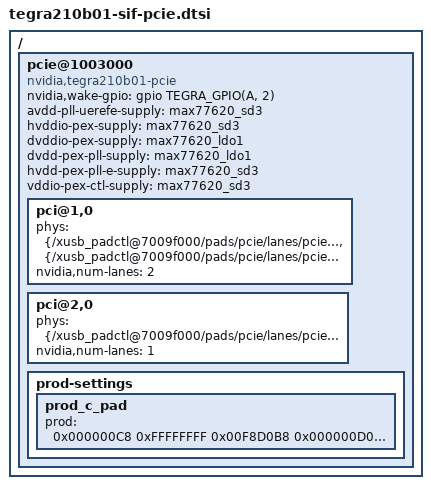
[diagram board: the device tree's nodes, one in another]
/*
 * tegra210b01-sif-pci.dtsi
 *
 * Copyright (c) 2018, NVIDIA CORPORATION.  All rights reserved.
 *
 * This program is free software; you can redistribute it and/or modify
 * it under the terms of the GNU General Public License as published by
 * the Free Software Foundation; version 2 of the License.
 *
 * This program is distributed in the hope that it will be useful, but WITHOUT
 * ANY WARRANTY; without even the implied warranty of MERCHANTABILITY or
 * FITNESS FOR A PARTICULAR PURPOSE.  See the GNU General Public License for
 * more details.
 *
 * You should have received a copy of the GNU General Public License along
 * with this program; if not, write to the Free Software Foundation, Inc.,
 * 51 Franklin Street, Fifth Floor, Boston, MA  02110-1301, USA.
 *
 */
/ {
	pcie@1003000 {
		compatible = "nvidia,tegra210b01-pcie";
		/delete-property/ iommus;
		/delete-property/ iommu-map;
		/delete-property/ iommu-map-mask;
		nvidia,wake-gpio = <&gpio TEGRA_GPIO(A, 2) 0>;
		avdd-pll-uerefe-supply = <&max77620_sd3>;
		hvddio-pex-supply = <&max77620_sd3>;
		dvddio-pex-supply = <&max77620_ldo1>;
		dvdd-pex-pll-supply = <&max77620_ldo1>;
		hvdd-pex-pll-e-supply = <&max77620_sd3>;
		vddio-pex-ctl-supply = <&max77620_sd3>;
		status = "okay";

		pci@1,0 {
			phys = <&{/xusb_padctl@7009f000/pads/pcie/lanes/pcie-3}>,
				<&{/xusb_padctl@7009f000/pads/pcie/lanes/pcie-2}>;
			phy-names = "pcie-0", "pcie-1";
			nvidia,num-lanes = <2>;
			status = "okay";
		};

		pci@2,0 {
			phys = <&{/xusb_padctl@7009f000/pads/pcie/lanes/pcie-0}>;
			phy-names = "pcie-0";
			nvidia,num-lanes = <1>;
			status = "okay";
		};

		prod-settings {
			prod_c_pad {
				prod = <
					0x000000C8 0xFFFFFFFF 0x00F8D0B8        // PADS_REFCLK_CFG0     31:0    0x00F8D0B8
					0x000000D0 0x00000038 0x0               // PADS_REFCLK_BIAS     5:3     0x0
					>;
			};
		};
	};
};
